# ms_ti_vcp2_rl_edma_bus_011 register map
Vendor: Texas Instruments
Peripheral module from a debugger description file (folder TCI6484_C6457).
Registers are 32-bit, access not given, reset 0x0 unless marked. A register's access mark holds for its fields unless they carry their own. Offsets are as the file gives them; lines under a group give offsets from that group; [hi:lo] are bit positions; {n}, {i} and the like mark numbered series; 'fields as' and 'values as' point back to an identical list; <NAME> marks a mode.

## VCP2 — Viterbi Coprocessor 2 (VCP2) is a programmable peripheral for decoding of convolutional codes, integrated into Texas Instruments' Curie DSP device
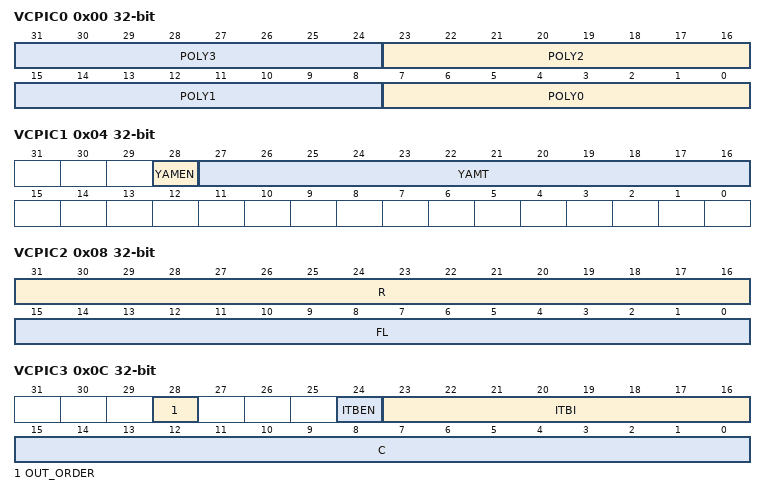
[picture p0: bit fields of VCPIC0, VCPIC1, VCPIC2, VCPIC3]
0x00 VCPIC0 rw — VCP input configuration register 0
  [8n+7:8n] POLY{n} (n=0..3) — Polynomial Generator G{n}.
0x04 VCPIC1 — VCP input configuration register 1
  [28] YAMEN rw — Yamamoto algorithm enable bit.
    0=DISABLE (Yamamoto algorithm is disabled); 1=ENABLE (Yamamoto algorithm is enabled)
  [27:16] YAMT rw — Yamamoto threshold value bits.
0x08 VCPIC2 rw — VCP input configuration register 2
  [31:16] R — Reliability length bits.
  [15:0] FL — Frame length bits.
0x0C VCPIC3 — VCP input configuration register 3
  [28] OUT_ORDER rw — This bit defines the order of VCP output for decoded data.
    0=LSB (0-31); 1=MSB (31-0)
  [24] ITBEN rw — Traceback state index enable/disable.
    0=DISABLE; 1=ENABLE
  [23:16] ITBI rw — Traceback state index.
  [15:0] C rw — Convergence distance bits.
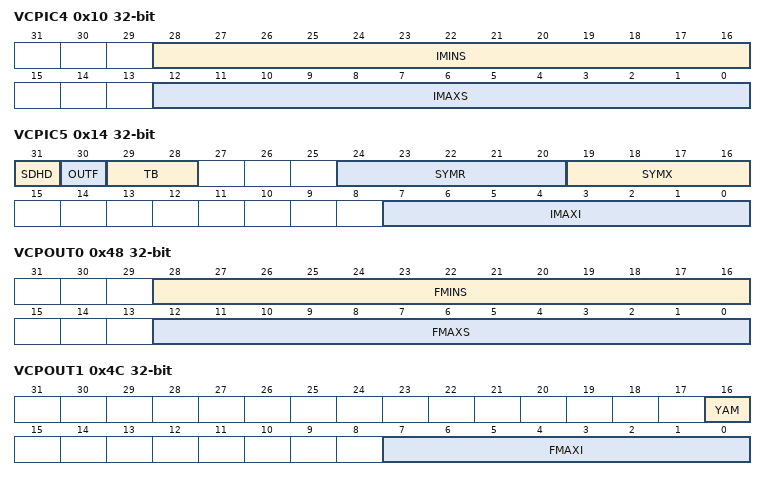
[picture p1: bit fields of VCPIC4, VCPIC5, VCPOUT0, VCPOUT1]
0x10 VCPIC4 — VCP input configuration register 4
  [28:16] IMINS rw — Minimum initial state metric value bits.
  [12:0] IMAXS rw — Maximum initial state metric value bits.
0x14 VCPIC5 — VCP input configuration register 5
  [31] SDHD rw — Output decision type select bit.
    0=HARD (Hard decisions); 1=SOFT (Soft decisions)
  [30] OUTF rw — Output parameters read flag bit.
    0=NO (VCP read event is not generated for output parameters read); 1=YES (VCP read event is generated for output parameters read)
  [29:28] TB rw — Traceback mode select bits.
    0=NO (Traceback not allowed); 1=TAIL (Tailed mode); 2=CONV (Convergent mode); 3=MIX (Mixed mode)
  [24:20] SYMR rw — These bits determine the decision buffer length in output FIFO.
  [19:16] SYMX rw — These bits determine the branch metric buffer length in input FIFO.
  [7:0] IMAXI rw — These bits determine the maximum initial state metric value.
0x48 VCPOUT0 — VCP output register 0
  [28:16] FMINS rw — Minimum initial state metric value for the final trellis stage.
  [12:0] FMAXS rw — Maximum state metric value for the final trellis stage.
0x4C VCPOUT1 — VCP output register 1
  [16] YAM ro — Yamamoto bit result.
    0=NO (At least one trellis stage had an absolute difference less than the Yamamoto threshold and the decoded frame has poor quality.); 1=YES (No trellis stage had an absolute difference less than the Yamamoto threshold and the frame has good quality.)
  [7:0] FMAXI ro — State index for the state with the final maximum state metric.
0x80 VCPWBM rw — VCP branch metrics write register
  [31:0] WRITE
0xC0 VCPRDECS ro — VCP decisions read register
  [31:0] READ
